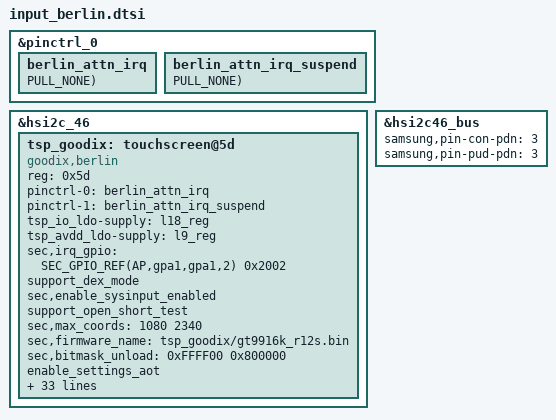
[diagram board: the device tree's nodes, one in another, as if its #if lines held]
&pinctrl_0 {
	berlin_attn_irq: berlin_attn_irq {
		GPIO_CONFIG_PUD(AP,gpa1,gpa1,2, FUNC_INPUT_WAKEUP, PULL_NONE);
	};

	berlin_attn_irq_suspend: berlin_attn_irq_suspend {
		GPIO_CONFIG_PUD(AP,gpa1,gpa1,2, FUNC_INPUT, PULL_NONE);
	};
};

&hsi2c_46 {
	#address-cells = <1>;
	#size-cells = <0>;
	status = "okay";

	tsp_goodix: touchscreen@5d {
		status = "okay";
		compatible = "goodix,berlin";
		reg = <0x5d>;
		pinctrl-names = "on_state", "off_state";
		pinctrl-0 = <&berlin_attn_irq>;
		pinctrl-1 = <&berlin_attn_irq_suspend>;
#if LEGO_IS_USE(l18_reg, ...)
		tsp_io_ldo-supply = <&l18_reg>;
#endif
#if LEGO_IS_USE(l9_reg, ...)
		tsp_avdd_ldo-supply = <&l9_reg>;
#endif
		sec,irq_gpio = <SEC_GPIO_REF(AP,gpa1,gpa1,2) 0x2002>;
		support_dex_mode;
		sec,enable_sysinput_enabled;
		support_open_short_test;
	};
};

/* /home/dpi/qb5_8814/workspace/P4_1716/android/kernel/kmodule/input/sec_input_2024/touchscreen/goodix/berlin/dts/input-lsi-tsp-berlin.r12s.dtsi */
&tsp_goodix {
	status = "okay";
	sec,enable_sysinput_enabled;
	sec,max_coords = <1080 2340>; /* x y */
	sec,firmware_name = "tsp_goodix/gt9916k_r12s.bin";
	sec,bitmask_unload = <0xFFFF00 0x800000>; /* bitshift bitmask. this is for synaptics panel */

	enable_settings_aot;
	support_ear_detect_mode;
	support_fod;
	support_fod_lp_mode;
	support_gesture_uevent;
	support_vbus_notifier;

	goodix,enable_esd_check;
	goodix,ic_type = <3>; //GT9916K

	goodix,max_drv_num = <17>;
	goodix,max_sen_num = <37>;
	goodix,drv_map = <40 41 42 43 44 45 46 47
					48 49 50 51 52 53 54 55 56 57 58 59>;
	goodix,sen_map = <0 1 2 3 4 5 6 7 8 9 10 11 12
					13 14 15 16 17 18 19 20 21 22 23 24
					25 26 27 28 29 30 31 32 33 34 35 36
					37 38 39>;
	goodix,short_test_time_reg = <0x14D7A>;
	goodix,short_test_status_reg = <0x13400>;
	goodix,short_test_result_reg = <0x13408>;
	goodix,drv_drv_reg = <0x1344E>;
	goodix,sen_sen_reg = <0x137E6>;
	goodix,drv_sen_reg = <0x14556>;
	goodix,diff_code_reg = <0x14D00>;
	goodix,production_test_addr = <0x0000>; //unused

	goodix,switch_freq_cmd = <0xB1>;
	goodix,switch_cfg_cmd = <0x64>;
	goodix,snr_cmd = <0x65>;
	goodix,sensitive_cmd = <0x66>;

	goodix,isp_ram_reg = <0x23800>;
	goodix,flash_cmd_reg = <0x12400>;
	goodix,isp_buffer_reg = <0x12410>;
	goodix,config_data_reg = <0x3E000>;
	goodix,misctl_reg = <0xD804>;
	goodix,watch_dog_reg = <0xD040>;
	goodix,config_id_reg = <0x10076>;
	goodix,enable_misctl_val = <0x20700000>;
};

&hsi2c46_bus {
	samsung,pin-con-pdn = <3>;
	samsung,pin-pud-pdn = <3>;
};
